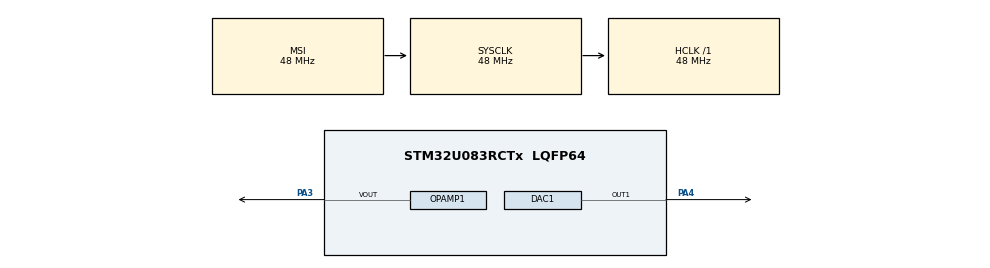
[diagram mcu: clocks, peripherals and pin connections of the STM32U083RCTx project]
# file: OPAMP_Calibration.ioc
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DAC1.DAC_Trigger-DAC_OUT1_ExtAndInt=DAC_TRIGGER_T2_TRGO
DAC1.WaveGeneration-DAC_OUT1_ExtAndInt=NoiseWaveGeneration
Dma.DAC1_CH1.0.Direction=DMA_MEMORY_TO_PERIPH
Dma.DAC1_CH1.0.EventEnable=DISABLE
Dma.DAC1_CH1.0.Instance=DMA1_Channel1
Dma.DAC1_CH1.0.MemDataAlignment=DMA_MDATAALIGN_HALFWORD
Dma.DAC1_CH1.0.MemInc=DMA_MINC_ENABLE
Dma.DAC1_CH1.0.Mode=DMA_NORMAL
Dma.DAC1_CH1.0.PeriphDataAlignment=DMA_PDATAALIGN_HALFWORD
Dma.DAC1_CH1.0.PeriphInc=DMA_PINC_DISABLE
Dma.DAC1_CH1.0.Polarity=HAL_DMAMUX_REQ_GEN_RISING
Dma.DAC1_CH1.0.Priority=DMA_PRIORITY_LOW
Dma.DAC1_CH1.0.RequestNumber=1
Dma.DAC1_CH1.0.SignalID=NONE
Dma.DAC1_CH1.0.SyncEnable=DISABLE
Dma.DAC1_CH1.0.SyncPolarity=HAL_DMAMUX_SYNC_NO_EVENT
Dma.DAC1_CH1.0.SyncRequestNumber=1
Dma.DAC1_CH1.0.SyncSignalID=NONE
Dma.Request0=DAC1_CH1
Mcu.Family=STM32U0
Mcu.Name=STM32U083RCTx
Mcu.Package=LQFP64
NVIC.DMA1_Channel1_IRQn=true\:0\:0\:false\:false\:true\:false\:true\:true
NVIC.PriorityGroup=NVIC_PRIORITYGROUP_2
NVIC.TIM6_DAC_LPTIM1_IRQn=true\:0\:0\:false\:false\:true\:true\:true\:true
PA3.Mode=Follower-DAC_OUT1-INP
PA3.Signal=OPAMP1_VOUT
PA4.Signal=COMP_DAC11_group
ProjectManager.HeapSize=0x200
ProjectManager.StackSize=0x400
ProjectManager.TargetToolchain=EWARM V9.20
RCC.ADCFreq_Value=48000000
RCC.AHBFreq_Value=48000000
RCC.CortexFreq_Value=48000000
RCC.HCLKFreq_Value=48000000
RCC.HSE_VALUE=4000000
RCC.HSI48_VALUE=48000000
RCC.HSI_VALUE=16000000
RCC.LSE_VALUE=32768
RCC.MSIClockRangeVal=RCC_MSIRANGE_11
RCC.MSI_VALUE=48000000
RCC.PLLM=RCC_PLLM_DIV8
RCC.PLLN=8
RCC.PLLSourceVirtual=RCC_PLLSOURCE_MSI
RCC.SYSCLKFreq_VALUE=48000000
RCC.SYSCLKSource=RCC_SYSCLKSOURCE_MSI
RCC.USBFreq_Value=48000000
RCC.VCOOutputFreq_Value=48000000
SH.COMP_DAC11_group.0=DAC1_OUT1,DAC_OUT1_ExtAndInt
TIM2.AutoReloadPreload=TIM_AUTORELOAD_PRELOAD_DISABLE
TIM2.ClockDivision=TIM_CLOCKDIVISION_DIV1
TIM2.CounterMode=TIM_COUNTERMODE_UP
TIM2.Period=0xFFFF
TIM2.Prescaler=0
TIM2.TIM_MasterOutputTrigger=TIM_TRGO_UPDATE
TIM2.TIM_MasterSlaveMode=TIM_MASTERSLAVEMODE_DISABLE
VP_PWR_VS_SECSignals.Mode=Security/Privilege
VP_TIM2_VS_ClockSourceINT.Mode=Internal
board=custom

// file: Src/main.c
/* USER CODE BEGIN Header */
/**
  ******************************************************************************
  * @file           : main.c
  * @brief          : Main program body
  ******************************************************************************
  * @attention
  *
  * Copyright (c) 2023 STMicroelectronics.
  * All rights reserved.
  *
  * This software is licensed under terms that can be found in the LICENSE file
  * in the root directory of this software component.
  * If no LICENSE file comes with this software, it is provided AS-IS.
  *
  ******************************************************************************
  */
/* USER CODE END Header */
#include "main.h"

/* USER CODE BEGIN Includes */
#include "stm32u0xx_nucleo.h"
/* USER CODE END Includes */

DAC_HandleTypeDef hdac1;
DMA_HandleTypeDef hdma_dac1_ch1;

OPAMP_HandleTypeDef hopamp1;

TIM_HandleTypeDef htim2;

/* USER CODE BEGIN PV */
/* Private variables ---------------------------------------------------------*/
__IO uint32_t UserButtonStatus = 0;  /* set to 1 after User push-button interrupt  */
__IO uint32_t UserButtonPressState = 0; /* Incremented at each press, representing application execution steps */

uint32_t factorytrimmingvaluep = 0, factorytrimmingvaluen = 0;
uint32_t oldtrimmingvaluep = 0, oldtrimmingvaluen = 0;
uint32_t newtrimmingvaluep = 0, newtrimmingvaluen = 0;

uint32_t ledblinkingduration = 0;

const uint16_t Sine12bit[32] = { 2000, 2390, 2765, 3111, 3414, 3662, 3847, 3961,
                                 4000, 3961, 3847, 3662, 3414, 3111, 2765, 2390,
                                 2000, 1609, 1234,  888,  585,  337,  152,   38,
                                 0,    38,   152,   337,  585,  888, 1234, 1609};

/* USER CODE END PV */

void SystemClock_Config(void);
static void MX_GPIO_Init(void);
static void MX_DMA_Init(void);
static void MX_TIM2_Init(void);
static void MX_OPAMP1_Init(void);
static void MX_DAC1_Init(void);
/* USER CODE BEGIN PFP */
/* Private function prototypes -----------------------------------------------*/
static void OPAMP_Calibrate_Before_Run (void);
static void OPAMP_Calibrate_After_Run(void);
/* USER CODE END PFP */

int main(void)
{

  /* MCU Configuration--------------------------------------------------------*/

  /* Reset of all peripherals, Initializes the Flash interface and the Systick. */
  HAL_Init();

  /* Configure the system clock */
  SystemClock_Config();

  /* Initialize all configured peripherals */
  MX_GPIO_Init();
  MX_DMA_Init();
  MX_TIM2_Init();
  MX_OPAMP1_Init();
  MX_DAC1_Init();
  /* USER CODE BEGIN 2 */
  /* Initialize LED on board */
  BSP_LED_Init(LED4);
  /* Configure User push-button in Interrupt mode */
  BSP_PB_Init(BUTTON_USER, BUTTON_MODE_EXTI);
  /* USER CODE END 2 */

  /* Infinite loop */
  /* USER CODE BEGIN WHILE */
  /*##- Start TIM2 peripheral counter ######################################*/
  if (HAL_TIM_Base_Start(&htim2) != HAL_OK)
  {
    /* TIM start error */
    Error_Handler();
  }

  /*##- Start DAC1 DAC_CHANNEL_2 and associated DMA1_Channel1 ##############################*/
  if (HAL_DAC_Start_DMA(&hdac1, DAC1_CHANNEL_1, (uint32_t*)Sine12bit,
                       32, DAC_ALIGN_12B_R) != HAL_OK)
  {
    /* Start DMA Error */
    Error_Handler();
  }

  /*##-1- Calibrate OPAMP1    #################################################*/

  /* Press user button to launch OPAMP1 calibration */
  while(UserButtonStatus != 1);
  HAL_Delay(200);
  UserButtonStatus = 0;
  UserButtonPressState++;

  OPAMP_Calibrate_Before_Run();

  /* Note: LED4 will blink:                                                 */
  /*       - quickly: Calibrated trimming are different from Factory Trimming */
  /*       - slowly : Calibrated trimming are     same as    Factory Trimming */

  /*##-2- Start OPAMP1    #####################################################*/

  /* Press user button to launch OPAMP1 */
  while(UserButtonStatus != 1)
  {
    BSP_LED_Toggle(LED4);
    HAL_Delay(ledblinkingduration);
  }
  BSP_LED_Off(LED4);
  HAL_Delay(200);
  UserButtonStatus = 0;
  UserButtonPressState++;

  /* Enable OPAMP1 */
  HAL_OPAMP_Start(&hopamp1);

  /*##-3- Modify OPAMP1 setting while ON ################################*/

  /* Press user button to change OPAMP1 setting on the fly (dummy change,      */
  /* without application purpose in this example: change non-inverting input  */
  /* source).                                                                 */
  while(UserButtonStatus != 1);
  HAL_Delay(200);
  UserButtonStatus = 0;
  UserButtonPressState++;

  /* Change the OPAMP1 input selection */
  hopamp1.Init.NonInvertingInput = OPAMP_NONINVERTINGINPUT_IO0;
  /* Update OPAMP1 config */
  HAL_OPAMP_Init(&hopamp1);

  /*##-4- Stop OPAMP1 #########################################################*/

  /* Press user button to stop OPAMP1 */
  while(UserButtonStatus != 1);
  HAL_Delay(200);
  UserButtonStatus = 0;
  UserButtonPressState++;

  /* Disable OPAMP1 */
  HAL_OPAMP_Stop(&hopamp1);

  /*##-5- Calibrate OPAMP1    #################################################*/

  /* Press user button to launch calibration */
  while(UserButtonStatus != 1);
  HAL_Delay(200);
  UserButtonStatus = 0;
  UserButtonPressState++;

  OPAMP_Calibrate_After_Run();

  /* Note: LED4 will blink:                                                               */
  /*       - quickly: New calibrated trimming are different from ones calibrated before run */
  /*       - slowly : New calibrated trimming are    same as     ones calibrated before run */

  while(UserButtonStatus != 1)
  {
    BSP_LED_Toggle (LED4);
    HAL_Delay(ledblinkingduration);
  }
  BSP_LED_Off(LED4);
  UserButtonPressState++;

  /*##-6- End of tests       #################################################*/

  while (1)
  {
    /* USER CODE END WHILE */

  }
}

void SystemClock_Config(void)
{
  RCC_OscInitTypeDef RCC_OscInitStruct = {0};
  RCC_ClkInitTypeDef RCC_ClkInitStruct = {0};

  /** Configure the main internal regulator output voltage
  */
  HAL_PWREx_ControlVoltageScaling(PWR_REGULATOR_VOLTAGE_SCALE1);

  /** Initializes the RCC Oscillators according to the specified parameters
  * in the RCC_OscInitTypeDef structure.
  */
  RCC_OscInitStruct.OscillatorType = RCC_OSCILLATORTYPE_MSI;
  RCC_OscInitStruct.MSIState = RCC_MSI_ON;
  RCC_OscInitStruct.MSICalibrationValue = RCC_MSICALIBRATION_DEFAULT;
  RCC_OscInitStruct.MSIClockRange = RCC_MSIRANGE_11;
  RCC_OscInitStruct.PLL.PLLState = RCC_PLL_NONE;
  if (HAL_RCC_OscConfig(&RCC_OscInitStruct) != HAL_OK)
  {
    Error_Handler();
  }

  /** Initializes the CPU, AHB and APB buses clocks
  */
  RCC_ClkInitStruct.ClockType = RCC_CLOCKTYPE_HCLK|RCC_CLOCKTYPE_SYSCLK
                              |RCC_CLOCKTYPE_PCLK1;
  RCC_ClkInitStruct.SYSCLKSource = RCC_SYSCLKSOURCE_MSI;
  RCC_ClkInitStruct.AHBCLKDivider = RCC_SYSCLK_DIV1;
  RCC_ClkInitStruct.APB1CLKDivider = RCC_HCLK_DIV1;

  if (HAL_RCC_ClockConfig(&RCC_ClkInitStruct, FLASH_LATENCY_1) != HAL_OK)
  {
    Error_Handler();
  }
}

static void MX_DAC1_Init(void)
{

  DAC_ChannelConfTypeDef sConfig = {0};

  /** DAC Initialization
  */
  hdac1.Instance = DAC1;
  if (HAL_DAC_Init(&hdac1) != HAL_OK)
  {
    Error_Handler();
  }

  /** DAC channel OUT1 config
  */
  sConfig.DAC_SampleAndHold = DAC_SAMPLEANDHOLD_DISABLE;
  sConfig.DAC_Trigger = DAC_TRIGGER_T2_TRGO;
  sConfig.DAC_OutputBuffer = DAC_OUTPUTBUFFER_ENABLE;
  sConfig.DAC_ConnectOnChipPeripheral = DAC_CHIPCONNECT_BOTH;
  sConfig.DAC_UserTrimming = DAC_TRIMMING_FACTORY;
  if (HAL_DAC_ConfigChannel(&hdac1, &sConfig, DAC_CHANNEL_1) != HAL_OK)
  {
    Error_Handler();
  }

  /** Configure Noise wave generation on DAC OUT1
  */
  if (HAL_DACEx_NoiseWaveGenerate(&hdac1, DAC_CHANNEL_1, DAC_LFSRUNMASK_BIT0) != HAL_OK)
  {
    Error_Handler();
  }

}

static void MX_OPAMP1_Init(void)
{

  hopamp1.Instance = OPAMP1;
  hopamp1.Init.PowerSupplyRange = OPAMP_POWERSUPPLY_LOW;
  hopamp1.Init.Mode = OPAMP_FOLLOWER_MODE;
  hopamp1.Init.NonInvertingInput = OPAMP_NONINVERTINGINPUT_DAC_CH;
  hopamp1.Init.PowerMode = OPAMP_POWERMODE_NORMALPOWER_NORMALSPEED;
  hopamp1.Init.UserTrimming = OPAMP_TRIMMING_FACTORY;
  if (HAL_OPAMP_Init(&hopamp1) != HAL_OK)
  {
    Error_Handler();
  }

}

static void MX_TIM2_Init(void)
{

  TIM_ClockConfigTypeDef sClockSourceConfig = {0};
  TIM_MasterConfigTypeDef sMasterConfig = {0};

  htim2.Instance = TIM2;
  htim2.Init.Prescaler = 0;
  htim2.Init.CounterMode = TIM_COUNTERMODE_UP;
  htim2.Init.Period = 0xFFFF;
  htim2.Init.ClockDivision = TIM_CLOCKDIVISION_DIV1;
  htim2.Init.AutoReloadPreload = TIM_AUTORELOAD_PRELOAD_DISABLE;
  if (HAL_TIM_Base_Init(&htim2) != HAL_OK)
  {
    Error_Handler();
  }
  sClockSourceConfig.ClockSource = TIM_CLOCKSOURCE_INTERNAL;
  if (HAL_TIM_ConfigClockSource(&htim2, &sClockSourceConfig) != HAL_OK)
  {
    Error_Handler();
  }
  sMasterConfig.MasterOutputTrigger = TIM_TRGO_UPDATE;
  sMasterConfig.MasterSlaveMode = TIM_MASTERSLAVEMODE_DISABLE;
  if (HAL_TIMEx_MasterConfigSynchronization(&htim2, &sMasterConfig) != HAL_OK)
  {
    Error_Handler();
  }

}

static void MX_DMA_Init(void)
{

  /* DMA controller clock enable */
  __HAL_RCC_DMA1_CLK_ENABLE();

  /* DMA interrupt init */
  /* DMA1_Channel1_IRQn interrupt configuration */
  HAL_NVIC_SetPriority(DMA1_Channel1_IRQn, 0, 0);
  HAL_NVIC_EnableIRQ(DMA1_Channel1_IRQn);

}

static void MX_GPIO_Init(void)
{

  /* GPIO Ports Clock Enable */
  __HAL_RCC_GPIOA_CLK_ENABLE();

}

/* USER CODE BEGIN 4 */

/**
  * @brief  OPAMP Calibration before OPAMP runs
  * @note
  * @note
  * @param  None
  * @retval None
  */
void OPAMP_Calibrate_Before_Run(void)
{

  /* Retrieve Factory Trimming */
   factorytrimmingvaluep = HAL_OPAMP_GetTrimOffset(&hopamp1, OPAMP_FACTORYTRIMMING_P);
   factorytrimmingvaluen = HAL_OPAMP_GetTrimOffset(&hopamp1, OPAMP_FACTORYTRIMMING_N);

   /* Run OPAMP calibration */
   HAL_OPAMP_SelfCalibrate(&hopamp1);

   /* Store trimming value */
   oldtrimmingvaluep = hopamp1.Init.TrimmingValueP;
   oldtrimmingvaluen = hopamp1.Init.TrimmingValueN;

   /* Are just calibrated trimming same or different from Factory Trimming */
   if  ((oldtrimmingvaluep != factorytrimmingvaluep) || (oldtrimmingvaluen != factorytrimmingvaluen))
   {
     /* Calibrated trimming are different from Factory Trimming */
     /* LED blinks quickly */
     ledblinkingduration = 250;
   }

   else
   {
     /* Calibrated trimming same as Factory Trimming */
    /* LED blinks slowly */
     ledblinkingduration = 1500;
   }

   /* With use temperature sensor   */
   /* Calibration */
}

/**
  * @brief  OPAMP Calibration after OPAMP runs
  * @note
  * @note
  * @param  None
  * @retval None
  */
void OPAMP_Calibrate_After_Run(void)
{
  /* Run OPAMP calibration */
  HAL_OPAMP_SelfCalibrate(&hopamp1);

  /* Store trimming value */
  newtrimmingvaluep = hopamp1.Init.TrimmingValueP;
  newtrimmingvaluen = hopamp1.Init.TrimmingValueN;

  /* Are just calibrated trimming same or different from Factory Trimming */
  if  ((oldtrimmingvaluep != newtrimmingvaluep) || (oldtrimmingvaluen != newtrimmingvaluen))
  {
    /* New calibrated trimming are different from ones calibrated before run */
    /* LED blinks quickly */
    ledblinkingduration = 250;
  }

  else
  {
    /* New calibrated trimming are same as ones calibrated before run */
    /* LED blinks slowly */
    ledblinkingduration = 1500;
  }
}

/**
  * @brief EXTI line detection callbacks
  * @param GPIO_Pin: Specifies the pins connected EXTI line
  * @retval None
  */
void HAL_GPIO_EXTI_Falling_Callback(uint16_t GPIO_Pin)
{
 if (GPIO_Pin == BUTTON_USER_PIN)
 {
   /* Set variable to report push button event to main program */
   UserButtonStatus = SET;
 }
}

/* USER CODE END 4 */

void Error_Handler(void)
{
  __disable_irq();
  while (1)
  {
  }
}
